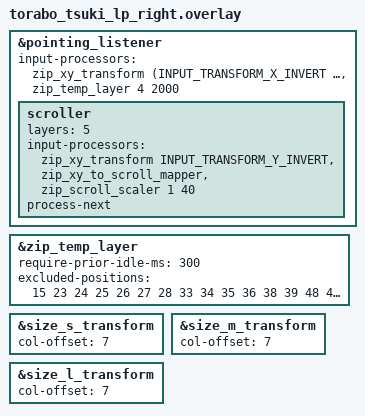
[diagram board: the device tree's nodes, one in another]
#define TORABO_TSUKI_LP_RIGHT 1

#include "torabo_tsuki_lp.dtsi"
#include <input/processors.dtsi>
#include <dt-bindings/zmk/input_transform.h>

&pointing_listener {
    input-processors = <&zip_xy_transform (INPUT_TRANSFORM_X_INVERT | INPUT_TRANSFORM_Y_INVERT)>,
                       <&zip_temp_layer 4 2000>;

    // Scroll layer: while layer 5 is held, ball movement becomes natural scrolling
    scroller {
        layers = <5>;
        input-processors = <&zip_xy_transform INPUT_TRANSFORM_Y_INVERT>,
                           <&zip_xy_to_scroll_mapper>,
                           <&zip_scroll_scaler 1 40>;
        process-next;
    };
};

// Auto mouse layer: keep layer 4 active while pressing clicks (K/L/;), scroll (J) or modifiers
&zip_temp_layer {
    require-prior-idle-ms = <300>;
    excluded-positions = <15 23 24 25 26 27 28 33 34 35 36 38 39 48 49 50 52 53 54>;
};

&size_s_transform {
    col-offset = <7>;
};

&size_m_transform {
    col-offset = <7>;
};

&size_l_transform {
    col-offset = <7>;
};
